# ATSAMR21E16A register map
Vendor: Atmel Corporation; Series: SAMR21; File version: A
CPU: CM0+ r0p1, little endian, no MPU, no FPU, VTOR, 2 interrupt priority bits
Registers are 8-bit, read-write, reset 0x0 unless marked. A register's access mark holds for its fields unless they carry their own. Offsets are from the block's base; [hi:lo] are bit positions; {n}, {i} and the like mark numbered series; 'fields as' and 'values as' point back to an identical list.

## AC — Analog Comparators
Base 0x42004400; register names take the prefix AC_
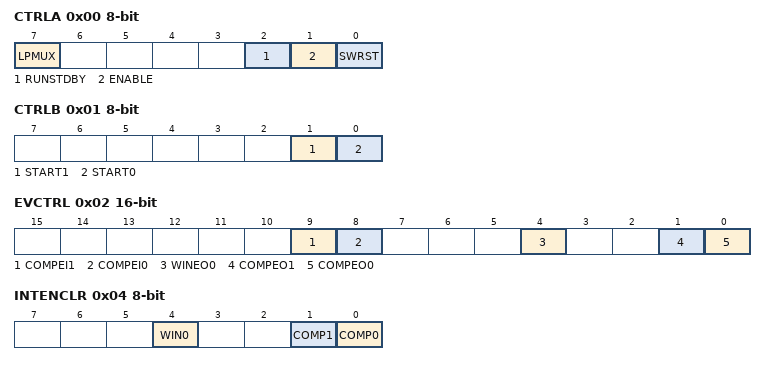
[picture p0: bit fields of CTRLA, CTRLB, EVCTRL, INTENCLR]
0x00 CTRLA — Control A
  [7] LPMUX — Low-Power Mux
  [2] RUNSTDBY — Run in Standby
  [1] ENABLE
  [0] SWRST wo — Software Reset
0x01 CTRLB wo — Control B
  [1] START1 — Comparator 1 Start Comparison
  [0] START0 — Comparator 0 Start Comparison
0x02 EVCTRL 16-bit — Event Control
  [9] COMPEI1 — Comparator 1 Event Input
  [8] COMPEI0 — Comparator 0 Event Input
  [4] WINEO0 — Window 0 Event Output Enable
  [1] COMPEO1 — Comparator 1 Event Output Enable
  [0] COMPEO0 — Comparator 0 Event Output Enable
0x04 INTENCLR — Interrupt Enable Clear
  [4] WIN0 — Window 0 Interrupt Enable
  [1] COMP1 — Comparator 1 Interrupt Enable
  [0] COMP0 — Comparator 0 Interrupt Enable
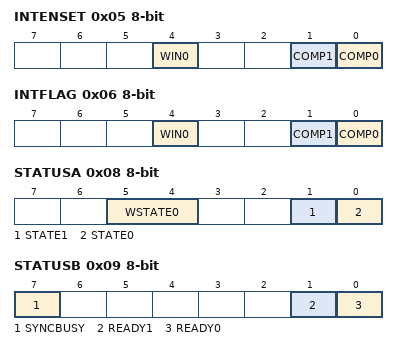
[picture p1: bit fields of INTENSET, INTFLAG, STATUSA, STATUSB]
0x05 INTENSET — Interrupt Enable Set
  fields as INTENCLR
0x06 INTFLAG — Interrupt Flag Status and Clear
  [4] WIN0 — Window 0
  [1] COMP1 — Comparator 1
  [0] COMP0 — Comparator 0
0x08 STATUSA ro
  [5:4] WSTATE0 — Window 0 Current State
    0=ABOVE (Signal is above window); 1=INSIDE (Signal is inside window); 2=BELOW (Signal is below window)
  [1] STATE1 — Comparator 1 Current State
  [0] STATE0 — Comparator 0 Current State
0x09 STATUSB ro
  [7] SYNCBUSY — Synchronization Busy
  [1] READY1 — Comparator 1 Ready
  [0] READY0 — Comparator 0 Ready
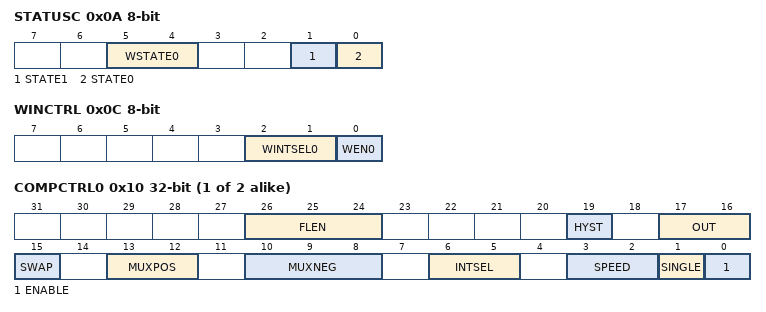
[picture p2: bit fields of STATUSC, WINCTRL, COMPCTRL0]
0x0A STATUSC ro
  fields as STATUSA
0x0C WINCTRL — Window Control
  [2:1] WINTSEL0 — Window 0 Interrupt Selection
    0=ABOVE (Interrupt on signal above window); 1=INSIDE (Interrupt on signal inside window); 2=BELOW (Interrupt on signal below window); 3=OUTSIDE (Interrupt on signal outside window)
  [0] WEN0 — Window 0 Mode Enable
{0x10+4i} COMPCTRL{i} (i=0..1) 32-bit — Comparator Control n
  [26:24] FLEN — Filter Length
    0=OFF (No filtering); 1=MAJ3 (3-bit majority function (2 of 3)); 2=MAJ5 (5-bit majority function (3 of 5))
  [19] HYST — Hysteresis Enable
  [17:16] OUT — Output
    0=OFF (The output of COMPn is not routed to the COMPn I/O port); 1=ASYNC (The asynchronous output of COMPn is routed to the COMPn I/O port); 2=SYNC (The synchronous output (including filtering) of COMPn is routed to the COMPn I/O port)
  [15] SWAP — Swap Inputs and Invert
  [13:12] MUXPOS — Positive Input Mux Selection
    {v}=PIN{v} (I/O pin {v}) (v=0..3)
  [10:8] MUXNEG — Negative Input Mux Selection
    {v}=PIN{v} (I/O pin {v}) (v=0..3); 4=GND (Ground); 5=VSCALE (VDD scaler); 6=BANDGAP (Internal bandgap voltage); 7=DAC (DAC output)
  [6:5] INTSEL — Interrupt Selection
    0=TOGGLE (Interrupt on comparator output toggle); 1=RISING (Interrupt on comparator output rising); 2=FALLING (Interrupt on comparator output falling); 3=EOC (Interrupt on end of comparison (single-shot mode only))
  [3:2] SPEED — Speed Selection
    0=LOW (Low speed); 1=HIGH (High speed)
  [1] SINGLE — Single-Shot Mode
  [0] ENABLE
{0x20+i} SCALER{i} (i=0..1) — Scaler n
  [5:0] VALUE — Scaler Value

## DMAC — Direct Memory Access Controller
Base 0x41004800; register names take the prefix DMAC_
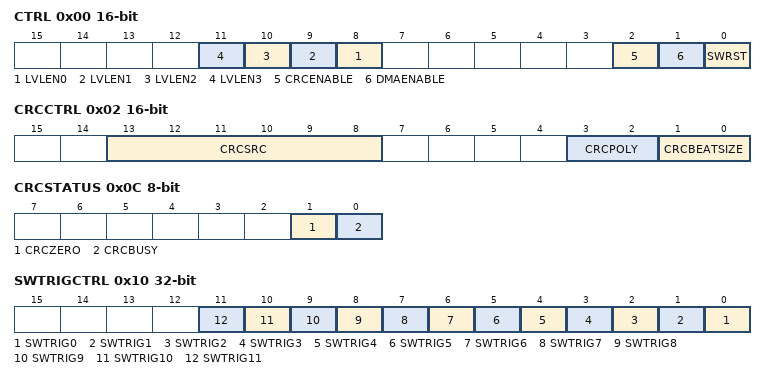
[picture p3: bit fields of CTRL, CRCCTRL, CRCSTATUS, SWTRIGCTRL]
0x00 CTRL 16-bit — Control
  [n+8] LVLEN{n} (n=0..3) — Priority Level {n} Enable
  [2] CRCENABLE
  [1] DMAENABLE
  [0] SWRST — Software Reset
0x02 CRCCTRL 16-bit — CRC Control
  [13:8] CRCSRC — CRC Input Source
    0=NOACT (No action); 1=IO (I/O interface)
  [3:2] CRCPOLY — CRC Polynomial Type
    0=CRC16 (CRC-16 (CRC-CCITT)); 1=CRC32 (CRC32 (IEEE 802.3))
  [1:0] CRCBEATSIZE
    0=BYTE (Byte bus access); 1=HWORD (Half-word bus access); 2=WORD (Word bus access)
0x04 CRCDATAIN 32-bit — CRC Data Input
0x08 CRCCHKSUM 32-bit — CRC Checksum
0x0C CRCSTATUS
  [1] CRCZERO ro
  [0] CRCBUSY — CRC Module Busy
0x0D DBGCTRL — Debug Control
  [0] DBGRUN — Debug Run
0x10 SWTRIGCTRL 32-bit — Software Trigger Control
  [n] SWTRIG{n} (n=0..11) — Channel {n} Software Trigger
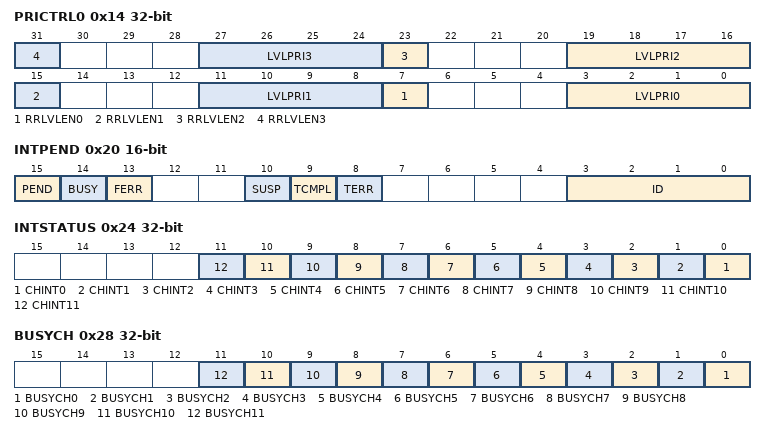
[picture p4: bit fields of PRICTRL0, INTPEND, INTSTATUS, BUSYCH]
0x14 PRICTRL0 32-bit — Priority Control 0
  [8n+7] RRLVLEN{n} (n=0..3) — Level {n} Round-Robin Scheduling Enable
  [8n+3:8n] LVLPRI{n} (n=0..3) — Level {n} Channel Priority Number
0x20 INTPEND 16-bit — Interrupt Pending
  [15] PEND ro — Pending
  [14] BUSY ro
  [13] FERR ro — Fetch Error
  [10] SUSP — Channel Suspend
  [9] TCMPL — Transfer Complete
  [8] TERR — Transfer Error
  [3:0] ID — Channel ID
0x24 INTSTATUS 32-bit ro — Interrupt Status
  [n] CHINT{n} (n=0..11) — Channel {n} Pending Interrupt
0x28 BUSYCH 32-bit ro — Busy Channels
  [n] BUSYCH{n} (n=0..11) — Busy Channel {n}
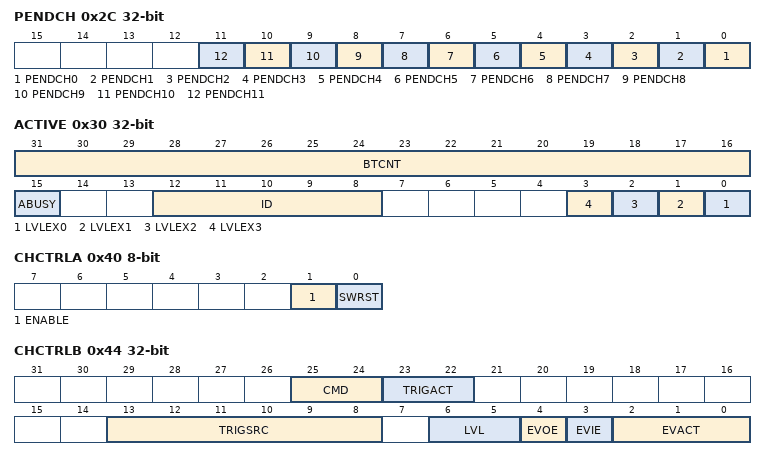
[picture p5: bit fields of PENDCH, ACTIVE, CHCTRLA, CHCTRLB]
0x2C PENDCH 32-bit ro — Pending Channels
  [n] PENDCH{n} (n=0..11) — Pending Channel {n}
0x30 ACTIVE 32-bit ro — Active Channel and Levels
  [31:16] BTCNT — Active Channel Block Transfer Count
  [15] ABUSY — Active Channel Busy
  [12:8] ID — Active Channel ID
  [n] LVLEX{n} (n=0..3) — Level {n} Channel Trigger Request Executing
0x34 BASEADDR 32-bit — Descriptor Memory Section Base Address
  [31:0] BASEADDR — Descriptor Memory Base Address
0x38 WRBADDR 32-bit — Write-Back Memory Section Base Address
  [31:0] WRBADDR — Write-Back Memory Base Address
0x3F CHID — Channel ID
  [3:0] ID
0x40 CHCTRLA — Channel Control A
  [1] ENABLE — Channel Enable
  [0] SWRST — Channel Software Reset
0x44 CHCTRLB 32-bit — Channel Control B
  [25:24] CMD — Software Command
    0=NOACT (No action); 1=SUSPEND (Channel suspend operation); 2=RESUME (Channel resume operation)
  [23:22] TRIGACT — Trigger Action
    0=BLOCK (One trigger required for each block transfer); 2=BEAT (One trigger required for each beat transfer); 3=TRANSACTION (One trigger required for each transaction)
  [13:8] TRIGSRC — Peripheral Trigger Source
    0=DISABLE (Only software/event triggers)
  [6:5] LVL — Channel Arbitration Level
  [4] EVOE — Channel Event Output Enable
  [3] EVIE — Channel Event Input Enable
  [2:0] EVACT — Event Input Action
    0=NOACT (No action); 1=TRIG (Transfer and periodic transfer trigger); 2=CTRIG (Conditional transfer trigger); 3=CBLOCK (Conditional block transfer); 4=SUSPEND (Channel suspend operation); 5=RESUME (Channel resume operation); 6=SSKIP (Skip next block suspend action)
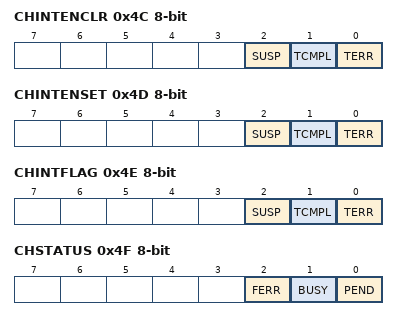
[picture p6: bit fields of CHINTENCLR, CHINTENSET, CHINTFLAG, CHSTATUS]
0x4C CHINTENCLR — Channel Interrupt Enable Clear
  [2] SUSP — Channel Suspend Interrupt Enable
  [1] TCMPL — Transfer Complete Interrupt Enable
  [0] TERR — Transfer Error Interrupt Enable
0x4D CHINTENSET — Channel Interrupt Enable Set
  fields as CHINTENCLR
0x4E CHINTFLAG — Channel Interrupt Flag Status and Clear
  [2] SUSP — Channel Suspend
  [1] TCMPL — Transfer Complete
  [0] TERR — Transfer Error
0x4F CHSTATUS ro — Channel Status
  [2] FERR — Fetch Error
  [1] BUSY — Channel Busy
  [0] PEND — Channel Pending

## Notices in the file
Atmel Microcontroller Software Support
Copyright (c) 2014, Atmel Corporation
All rights reserved.
Redistribution and use in source and binary forms, with or without
modification, are permitted provided that the following condition is met:
- Redistributions of source code must retain the above copyright notice,
this list of conditions and the disclaimer below.
Atmel's name may not be used to endorse or promote products derived from
this software without specific prior written permission.
DISCLAIMER: THIS SOFTWARE IS PROVIDED BY ATMEL "AS IS" AND ANY EXPRESS OR
IMPLIED WARRANTIES, INCLUDING, BUT NOT LIMITED TO, THE IMPLIED WARRANTIES OF
MERCHANTABILITY, FITNESS FOR A PARTICULAR PURPOSE AND NON-INFRINGEMENT ARE
DISCLAIMED. IN NO EVENT SHALL ATMEL BE LIABLE FOR ANY DIRECT, INDIRECT,
INCIDENTAL, SPECIAL, EXEMPLARY, OR CONSEQUENTIAL DAMAGES (INCLUDING, BUT NOT
LIMITED TO, PROCUREMENT OF SUBSTITUTE GOODS OR SERVICES; LOSS OF USE, DATA,
OR PROFITS; OR BUSINESS INTERRUPTION) HOWEVER CAUSED AND ON ANY THEORY OF
LIABILITY, WHETHER IN CONTRACT, STRICT LIABILITY, OR TORT (INCLUDING
NEGLIGENCE OR OTHERWISE) ARISING IN ANY WAY OUT OF THE USE OF THIS SOFTWARE,
EVEN IF ADVISED OF THE POSSIBILITY OF SUCH DAMAGE.
